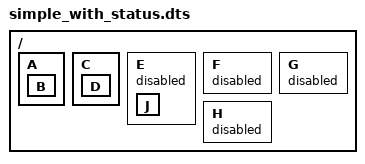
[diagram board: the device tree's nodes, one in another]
// Copyright 2025 The Fuchsia Authors. All rights reserved.
// Use of this source code is governed by a BSD-style license that can be
// found in the LICENSE file.

/dts-v1/;

/*
             root
     /     /      \    \   \   \
    A     C        E    F   G   H
   /       \        \
  B         D        J
*/

/ {
        A {
                B {
                };
        };
        C {
                status = "okay";
                D {
                        status = "ok";
                };
        };
        E {
                status = "disabled";
                J {
                };
        };
        F {
                status = "fail";
        };
        G {
                status = "fail-123";
        };
        H {
                status = "random-value";
        };
};
